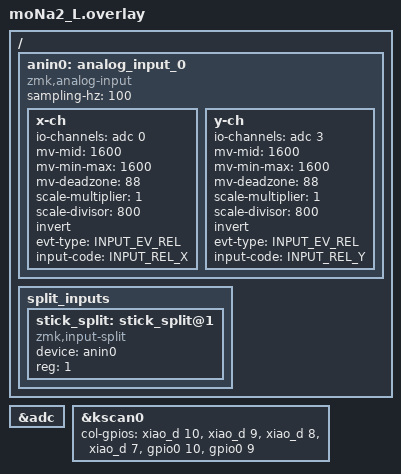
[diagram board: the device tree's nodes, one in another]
#include <zephyr/dt-bindings/input/input-event-codes.h>
#include <input/processors.dtsi>
#include <dt-bindings/zmk/input_transform.h>
#include "moNa2.dtsi"

&adc {
	status = "okay";
};

&kscan0 {
        col-gpios
            = <&xiao_d 10 GPIO_ACTIVE_HIGH>
            , <&xiao_d 9 GPIO_ACTIVE_HIGH> 
            , <&xiao_d 8 GPIO_ACTIVE_HIGH> 
            , <&xiao_d 7 GPIO_ACTIVE_HIGH> 
            , <&gpio0 10 GPIO_ACTIVE_HIGH>
            , <&gpio0 9 GPIO_ACTIVE_HIGH>
            ;
};

/ {
    anin0: analog_input_0 {
        compatible = "zmk,analog-input";
        sampling-hz = <100>;
        x-ch {
            io-channels = <&adc 0>;
            mv-mid = <1600>;
            mv-min-max = <1600>;
            mv-deadzone = <88>;
            scale-multiplier = <1>;
            scale-divisor = <800>;
            invert;
            evt-type = <INPUT_EV_REL>;
            input-code = <INPUT_REL_X>;
        };
        y-ch {
            io-channels = <&adc 3>;
            mv-mid = <1600>;
            mv-min-max = <1600>;
            mv-deadzone = <88>;
            scale-multiplier = <1>;
            scale-divisor = <800>;
            invert;
            evt-type = <INPUT_EV_REL>;
            input-code = <INPUT_REL_Y>;
        };
    };

    split_inputs {
        #address-cells = <1>;
        #size-cells = <0>;

        stick_split: stick_split@1 {
            compatible = "zmk,input-split";
            status = "okay";
            device = <&anin0>;
            reg = <1>;
        };
    };
};
